# ATtiny40 device description
Architecture: AVR8L; Family: tinyAVR
Registers are 8-bit, access not given, no defined reset value unless marked. A register's access mark holds for its fields unless they carry their own. Offsets are from the block's base; [hi:lo] are bit positions; {n}, {i} and the like mark numbered series.

## LOCKBIT — Lockbits
Instances: LOCKBIT 0 in lockbits
0x00 LOCKBIT
  [1:0] LB — Memory Lock
    0=PROG_VER_DISABLED (Further programming and verification disabled); 2=PROG_DISABLED (Further programming disabled); 3=NO_LOCK (No memory lock features enabled)

## WDT — Watchdog Timer
Instances: WDT 0x00
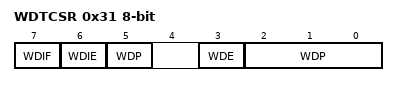
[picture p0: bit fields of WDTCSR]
0x31 WDTCSR — Watchdog Timer Control and Status Register
  [7] WDIF — Watchdog Timer Interrupt Flag
  [6] WDIE — Watchdog Timer Interrupt Enable
  [3] WDE — Watch Dog Enable
  [5,2:0] WDP — Watchdog Timer Prescaler Bits
    0=Oscillator Cycles 2K; 1=Oscillator Cycles 4K; 2=Oscillator Cycles 8K; 3=Oscillator Cycles 16K; 4=Oscillator Cycles 32K; 5=Oscillator Cycles 64K; 6=Oscillator Cycles 128K; 7=Oscillator Cycles 256K; 8=Oscillator Cycles 512K; 9=Oscillator Cycles 1024K

## ADC — Analog-to-Digital Converter
Instances: ADC 0x00
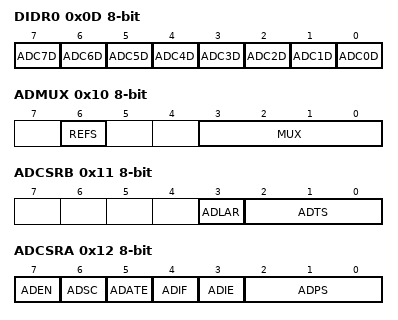
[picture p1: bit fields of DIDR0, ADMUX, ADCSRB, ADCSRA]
0x0D DIDR0 — Digital Input Disable Register 0
  [n] ADC{n}D (n=4..7) — ADC{n-1} Digital input Disable
  [3] ADC3D — AREF Digital Input Disable
  [2] ADC2D — ADC2 Digital input Disable
  [1] ADC1D — ADC1 Digital input Disable
  [0] ADC0D — ADC0 Digital input Disable
0x0E ADC 16-bit — ADC Data Register Bytes
0x10 ADMUX — The ADC multiplexer Selection Register
  [6] REFS — Reference Selection Bit
    0=Vcc used as internal reference; 1=Internal 1.1V Referemce
  [3:0] MUX — Analog Channel and Gain Selection Bits
    {v}=ADC{v} (v=0..11); 12=ADC_GND (0V (AGND)); 13=ADC_VBG (1.1V Internal Reference); 14=TEMPSENS (Temperature sensor)
0x11 ADCSRB — ADC Control and Status Register B
  [3] ADLAR
  [2:0] ADTS — ADC Auto Trigger Sources
    0=Free Running mode; 1=Analog Comparator; 2=External Interrupt Request 0; 3=Timer/Counter0 Compare Match A; 4=Timer/Counter0 Overflow; 5=Timer/Counter1 Compare Match B; 6=Timer/Counter1 Overflow; 7=Watchdog Interrupt Request
0x12 ADCSRA — The ADC Control and Status register
  [7] ADEN — ADC Enable
  [6] ADSC — ADC Start Conversion
  [5] ADATE — ADC Auto Trigger Enable
  [4] ADIF — ADC Interrupt Flag
  [3] ADIE — ADC Interrupt Enable
  [2:0] ADPS — ADC Prescaler Select Bits
    0=2; 1=2; 2=4; 3=8; 4=16; 5=32; 6=64; 7=128

## AC — Analog Comparator
Instances: AC 0x00
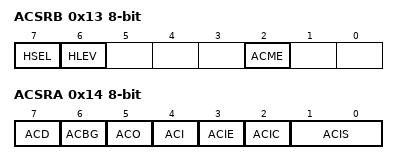
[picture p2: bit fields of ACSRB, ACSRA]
0x13 ACSRB — Analog Comparator Control And Status Register B
  [7] HSEL — Hysteresis Select
  [6] HLEV — Hysteresis Level
  [2] ACME — Analog Comparator Multiplexer Enable
0x14 ACSRA — Analog Comparator Control And Status Register A
  [7] ACD — Analog Comparator Disable
  [6] ACBG — Analog Comparator Bandgap Select
  [5] ACO — Analog Compare Output
  [4] ACI — Analog Comparator Interrupt Flag
  [3] ACIE — Analog Comparator Interrupt Enable
  [2] ACIC — Analog Comparator Input Capture Enable
  [1:0] ACIS — Analog Comparator Interrupt Mode Select bits
    0=Interrupt on Toggle; 2=Interrupt on Falling Edge; 3=Interrupt on Rising Edge

## TWI — Two Wire Serial Interface
Instances: TWI 0x00
0x28 TWSD — TWI Slave Data Register
  [7:0] TWSD — TWI slave data bit
0x29 TWSAM — TWI Slave Address Mask Register
0x2A TWSA — TWI Slave Address Register
  [7:0] TWSA — TWI slave address bit
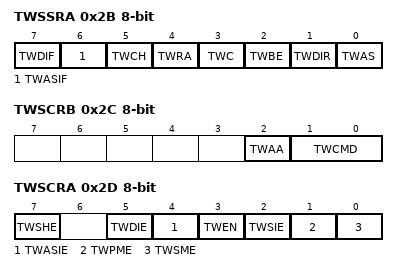
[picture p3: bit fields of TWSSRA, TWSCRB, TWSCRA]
0x2B TWSSRA — TWI Slave Status Register A
  [7] TWDIF — TWI Data Interrupt Flag
  [6] TWASIF — TWI Address/Stop Interrupt Flag
  [5] TWCH — TWI Clock Hold
  [4] TWRA — TWI Receive Acknowledge
  [3] TWC — TWI Collision
  [2] TWBE — TWI Bus Error
  [1] TWDIR — TWI Read/Write Direction
  [0] TWAS — TWI Address or Stop
0x2C TWSCRB — TWI Slave Control Register B
  [2] TWAA — TWI Acknowledge Action
  [1:0] TWCMD
0x2D TWSCRA — TWI Slave Control Register A
  [7] TWSHE — TWI SDA Hold Time Enable
  [5] TWDIE — TWI Data Interrupt Enable
  [4] TWASIE — TWI Address/Stop Interrupt Enable
  [3] TWEN — Two-Wire Interface Enable
  [2] TWSIE — TWI Stop Interrupt Enable
  [1] TWPME — TWI Promiscuous Mode Enable
  [0] TWSME — TWI Smart Mode Enable
